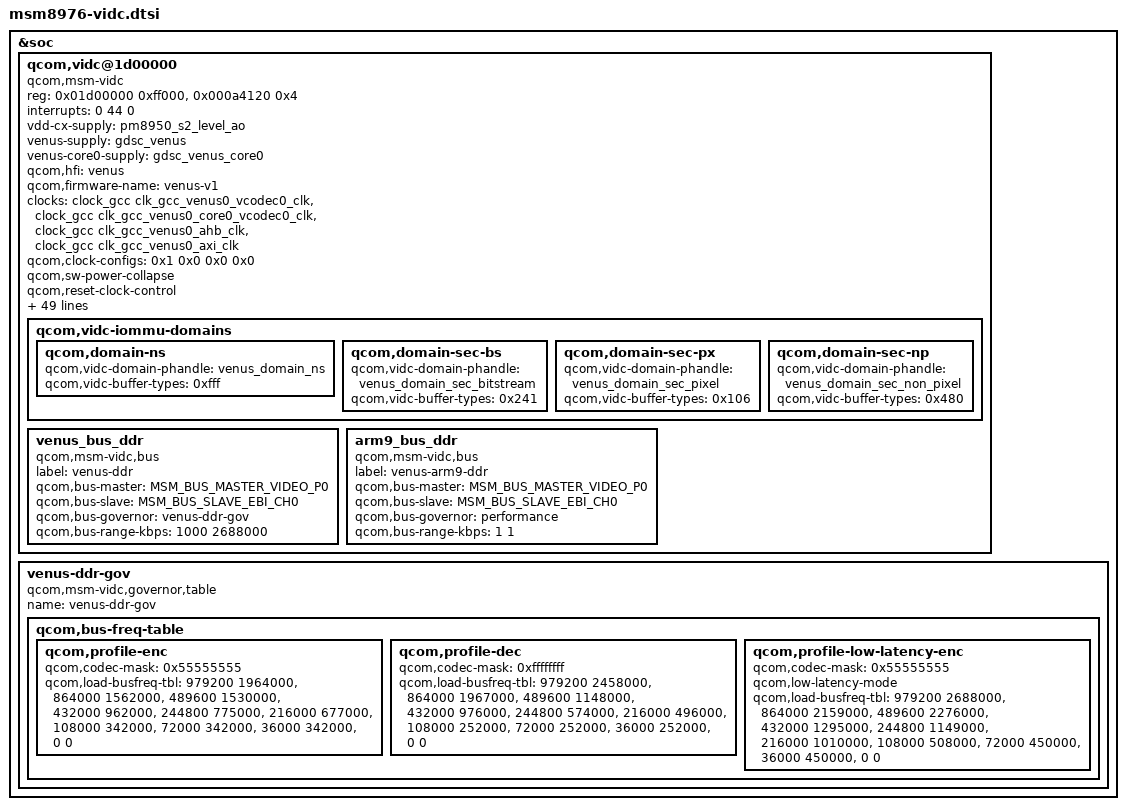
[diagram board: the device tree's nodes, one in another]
/* Copyright (c) 2015-2016, The Linux Foundation. All rights reserved.
 *
 * This program is free software; you can redistribute it and/or modify
 * it under the terms of the GNU General Public License version 2 and
 * only version 2 as published by the Free Software Foundation.
 *
 * This program is distributed in the hope that it will be useful,
 * but WITHOUT ANY WARRANTY; without even the implied warranty of
 * MERCHANTABILITY or FITNESS FOR A PARTICULAR PURPOSE.  See the
 * GNU General Public License for more details.
 */

&soc {
	qcom,vidc@1d00000 {
		compatible = "qcom,msm-vidc";
		reg = <0x01d00000 0xff000>,
			<0x000a4120 0x4>;
		reg-names = "vidc", "efuse";
		interrupts = <0 44 0>;
		vdd-cx-supply = <&pm8950_s2_level_ao>;
		venus-supply = <&gdsc_venus>;
		venus-core0-supply = <&gdsc_venus_core0>;
		qcom,hfi = "venus";
		qcom,firmware-name = "venus-v1";

		clocks =
			<&clock_gcc clk_gcc_venus0_vcodec0_clk>,
			<&clock_gcc clk_gcc_venus0_core0_vcodec0_clk>,
			<&clock_gcc clk_gcc_venus0_ahb_clk>,
			<&clock_gcc clk_gcc_venus0_axi_clk>;

		clock-names = "core_clk", "core0_clk", "iface_clk", "bus_clk";
		qcom,clock-configs = <0x1 0x0 0x0 0x0>;
		qcom,sw-power-collapse;
		qcom,reset-clock-control;
		qcom,regulator-scaling;
		qcom,max-hw-load = <1044480>; /* 4096 x 2176 @ 30 fps */
		qcom,dcvs-tbl =
			/* Dec UHD@30 H.264, HEVC, VP8, VP9 - NOM to NOM+*/
			<816000 816000 979200 0x3f00000c>,

			/* Enc 3840x1920@30 H.264/HEVC Turbo to Nom+ */
			<855000 821100 979200 0x4000004>,

			/* Enc True4K@24 H.264/HEVC Nom to Nom+ */
			<816000 720000 835584 0x4000004>;
		qcom,dcvs-limit =
			<28800 24>, /* Encoder 3840x1920 */
			<32400 24>; /* Decoder UHD */

		qcom,load-freq-tbl =
			<979200 466000000 0x55555555>, /* TURBO, UHD30E   */
			<979200 400000000 0xffffffff>, /* NOM+ , UHD30D   */
			<734400 360000000 0xffffffff>, /* NOM  , 1080p90D */
			<734400 400000000 0x55555555>, /* NOM+ , 1080p90E */
			<489600 228570000 0xffffffff>, /* SVS  , 1080p60D */
			<489600 466000000 0x55555555>, /* TURBO, 1080p60E */
			<432000 228570000 0xffffffff>, /* SVS  , 720p120D */
			<432000 400000000 0x55555555>, /* NOM+ , 720p120E */
			<244800 133333333 0xffffffff>, /* SVS- , 1080p30D */
			<244800 228570000 0x55555555>, /* SVS  , 1080p30E */
			<216000 100000000 0xffffffff>, /* SVS- , 720p60D  */
			<216000 228570000 0x55555555>, /* SVS  , 720p60E  */
			<108000 80000000 0xffffffff>,  /* SVS--, 720p30D  */
			<108000 100000000 0x55555555>, /* SVS- , 720p30E  */
			<36000 72727200 0xffffffff>,   /* SVS--, 480p30D  */
			<36000 80000000 0x55555555>;   /* SVS--, 480p30E  */

		qcom,qdss-presets =
			<0x6025000 0x1000>,
			<0x6026000 0x1000>,
			<0x6021000 0x1000>,
			<0x6002000 0x1000>,
			<0x9180000 0x1000>,
			<0x9181000 0x1000>;

		qcom,reg-presets =
			<0xE0020 0x05555556>,
			<0xE0024 0x05555556>,
			<0x80124 0x00000003>;

		qcom,clock-voltage-tbl =
			<72727200 RPM_SMD_REGULATOR_LEVEL_SVS>,
			<80000000 RPM_SMD_REGULATOR_LEVEL_SVS>,
			<100000000 RPM_SMD_REGULATOR_LEVEL_SVS>,
			<133333333 RPM_SMD_REGULATOR_LEVEL_SVS>,
			<228570000 RPM_SMD_REGULATOR_LEVEL_SVS>,
			<310667000 RPM_SMD_REGULATOR_LEVEL_SVS_PLUS>,
			<360000000 RPM_SMD_REGULATOR_LEVEL_NOM>,
			<400000000 RPM_SMD_REGULATOR_LEVEL_NOM_PLUS>,
			<466000000 RPM_SMD_REGULATOR_LEVEL_TURBO>;

		qcom,vp9d-clock-voltage-tbl =
			<72727200 RPM_SMD_REGULATOR_LEVEL_SVS>,
			<80000000 RPM_SMD_REGULATOR_LEVEL_SVS>,
			<100000000 RPM_SMD_REGULATOR_LEVEL_SVS>,
			<133333333 RPM_SMD_REGULATOR_LEVEL_SVS>,
			<228570000 RPM_SMD_REGULATOR_LEVEL_SVS_PLUS>,
			<310667000 RPM_SMD_REGULATOR_LEVEL_NOM>,
			<360000000 RPM_SMD_REGULATOR_LEVEL_NOM_PLUS>,
			<400000000 RPM_SMD_REGULATOR_LEVEL_TURBO>;

		qcom,vidc-iommu-domains {
			qcom,domain-ns {
				qcom,vidc-domain-phandle = <&venus_domain_ns>;
				qcom,vidc-buffer-types = <0xfff>;
			};

			qcom,domain-sec-bs {
				qcom,vidc-domain-phandle = <&venus_domain_sec_bitstream>;
				qcom,vidc-buffer-types = <0x241>;
			};

			qcom,domain-sec-px {
				qcom,vidc-domain-phandle = <&venus_domain_sec_pixel>;
				qcom,vidc-buffer-types = <0x106>;
			};

			qcom,domain-sec-np {
				qcom,vidc-domain-phandle = <&venus_domain_sec_non_pixel>;
				qcom,vidc-buffer-types = <0x480>;
			};
		};

		venus_bus_ddr {
			compatible = "qcom,msm-vidc,bus";
			label = "venus-ddr";
			qcom,bus-master = <MSM_BUS_MASTER_VIDEO_P0>;
			qcom,bus-slave = <MSM_BUS_SLAVE_EBI_CH0>;
			qcom,bus-governor = "venus-ddr-gov";
			qcom,bus-range-kbps = <1000 2688000>;
		};

		arm9_bus_ddr {
			compatible = "qcom,msm-vidc,bus";
			label = "venus-arm9-ddr";
			qcom,bus-master = <MSM_BUS_MASTER_VIDEO_P0>;
			qcom,bus-slave = <MSM_BUS_SLAVE_EBI_CH0>;
			qcom,bus-governor = "performance";
			qcom,bus-range-kbps = <1 1>;
		};
	};

	venus-ddr-gov {
		compatible = "qcom,msm-vidc,governor,table";
		name = "venus-ddr-gov";
		status = "ok";
		qcom,bus-freq-table {
			qcom,profile-enc {
				qcom,codec-mask = <0x55555555>;
				qcom,load-busfreq-tbl =
					<979200 1964000>,  /* UHD30E     */
					<864000 1562000>,  /* 720p240LPE */
					<489600 1530000>,  /* 1080p60E   */
					<432000 962000>,   /* 720p120E   */
					<244800 775000>,   /* 1080p30E   */
					<216000 677000>,   /* 720p60E    */
					<108000 342000>,   /* 720p30E    */
					<72000  342000>,   /* VGA60E     */
					<36000  342000>,   /* VGA30E     */
					<0 0>;
			};
			qcom,profile-dec {
				qcom,codec-mask = <0xffffffff>;
				qcom,load-busfreq-tbl =
					<979200 2458000>,  /* UHD30D     */
					<864000 1967000>,  /* 720p240D   */
					<489600 1148000>,  /* 1080p60D   */
					<432000 976000>,   /* 720p120D   */
					<244800 574000>,   /* 1080p30D   */
					<216000 496000>,   /* 720p60D    */
					<108000 252000>,   /* 720p30D    */
					<72000  252000>,   /* VGA60D     */
					<36000  252000>,   /* VGA30D     */
					<0 0>;
			};
			qcom,profile-low-latency-enc {
				qcom,codec-mask = <0x55555555>;
				qcom,low-latency-mode;
				qcom,load-busfreq-tbl =
					<979200 2688000>,  /* UHD30E     */
					<864000 2159000>,  /* 720p240LPE */
					<489600 2276000>,  /* 1080p60E   */
					<432000 1295000>,  /* 720p120E   */
					<244800 1149000>,  /* 1080p30E   */
					<216000 1010000>,  /* 720p60E    */
					<108000 508000>,   /* 720p30E    */
					<72000  450000>,   /* VGA60E     */
					<36000  450000>,   /* VGA30E     */
					<0 0>;
			};
		};
	};
};
